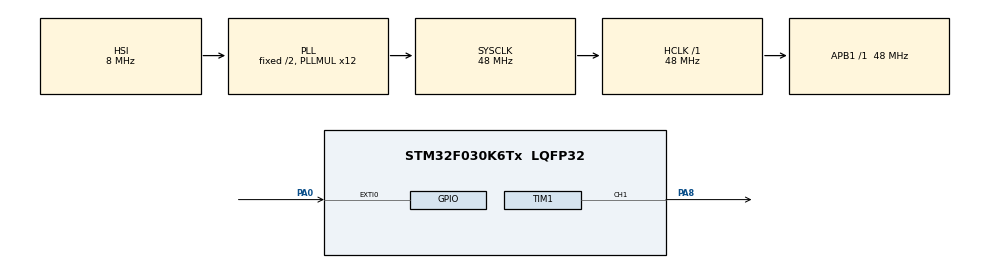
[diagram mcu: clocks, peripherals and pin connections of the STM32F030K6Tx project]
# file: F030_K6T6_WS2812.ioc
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Dma.Request0=TIM1_CH1
Dma.TIM1_CH1.0.Direction=DMA_MEMORY_TO_PERIPH
Dma.TIM1_CH1.0.Instance=DMA1_Channel2
Dma.TIM1_CH1.0.MemDataAlignment=DMA_MDATAALIGN_HALFWORD
Dma.TIM1_CH1.0.MemInc=DMA_MINC_DISABLE
Dma.TIM1_CH1.0.Mode=DMA_NORMAL
Dma.TIM1_CH1.0.PeriphDataAlignment=DMA_PDATAALIGN_HALFWORD
Dma.TIM1_CH1.0.PeriphInc=DMA_PINC_ENABLE
Dma.TIM1_CH1.0.Priority=DMA_PRIORITY_HIGH
Mcu.Family=STM32F0
Mcu.Name=STM32F030K6Tx
Mcu.Package=LQFP32
NVIC.DMA1_Channel2_3_IRQn=true\:1\:0\:true\:false\:true\:false\:true
NVIC.EXTI0_1_IRQn=true\:0\:0\:false\:false\:true\:true\:true
PA0.GPIO_ModeDefaultEXTI=GPIO_MODE_IT_FALLING
PA0.GPIO_PuPd=GPIO_PULLUP
PA0.Signal=GPXTI0
PA13.Mode=Serial_Wire
PA13.Signal=SYS_SWDIO
PA14.Mode=Serial_Wire
PA14.Signal=SYS_SWCLK
PA8.GPIO_Speed=GPIO_SPEED_FREQ_HIGH
PA8.Signal=S_TIM1_CH1
ProjectManager.HeapSize=0x200
ProjectManager.StackSize=0x400
ProjectManager.TargetToolchain=MDK-ARM V5.27
RCC.AHBFreq_Value=48000000
RCC.APB1Freq_Value=48000000
RCC.APB1TimFreq_Value=48000000
RCC.HCLKFreq_Value=48000000
RCC.PLLMUL=RCC_PLL_MUL12
RCC.SYSCLKFreq_VALUE=48000000
RCC.SYSCLKSource=RCC_SYSCLKSOURCE_PLLCLK
SH.S_TIM1_CH1.0=TIM1_CH1,PWM Generation1 CH1
TIM1.Channel-PWM\ Generation1\ CH1=TIM_CHANNEL_1
TIM1.Period=59
board=custom

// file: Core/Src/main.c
/* USER CODE BEGIN Header */
/**
  ******************************************************************************
  * @file           : main.c
  * @brief          : Main program body
  ******************************************************************************
  * @attention
  *
  * <h2><center>&copy; Copyright (c) 2022 STMicroelectronics.
  * All rights reserved.</center></h2>
  *
  * This software component is licensed by ST under BSD 3-Clause license,
  * the "License"; You may not use this file except in compliance with the
  * License. You may obtain a copy of the License at:
  *                        opensource.org/licenses/BSD-3-Clause
  *
  ******************************************************************************
  */
/* USER CODE END Header */
#include "main.h"

/* USER CODE BEGIN Includes */
#include "RGB_LED.h"
/* USER CODE END Includes */

/* USER CODE BEGIN PM */
#define NUM 60
uint16_t send_Buf[NUM] ={20};
/* USER CODE END PM */

TIM_HandleTypeDef htim1;
DMA_HandleTypeDef hdma_tim1_ch1;

void SystemClock_Config(void);
static void MX_GPIO_Init(void);
static void MX_DMA_Init(void);
static void MX_TIM1_Init(void);

/* USER CODE BEGIN 0 */
int i=0,biu=0;
/* USER CODE END 0 */

int main(void)
{

  /* MCU Configuration--------------------------------------------------------*/

  /* Reset of all peripherals, Initializes the Flash interface and the Systick. */
  HAL_Init();

  /* Configure the system clock */
  SystemClock_Config();

  /* Initialize all configured peripherals */
  MX_GPIO_Init();
  MX_DMA_Init();
  MX_TIM1_Init();
  /* USER CODE BEGIN 2 */
    for (i = 0; i < 8; i++)
    {
        send_Buf[i] =40 ;
    }
    for (i = 8; i < 24; i++)
    {
        send_Buf[i] =20 ;
    }

  /* USER CODE END 2 */

  /* Infinite loop */
  while (1)
  {

    /* USER CODE BEGIN 3 */
      HAL_TIM_PWM_Start_DMA(&htim1, TIM_CHANNEL_1,(uint32_t*)send_Buf,NUM);

      HAL_Delay(2000);
      HAL_TIM_PWM_Start_DMA(&htim1, TIM_CHANNEL_1,(uint32_t*)send_Buf,2);

      HAL_Delay(2000);

  }
  /* USER CODE END 3 */
}

void SystemClock_Config(void)
{
  RCC_OscInitTypeDef RCC_OscInitStruct = {0};
  RCC_ClkInitTypeDef RCC_ClkInitStruct = {0};

  /** Initializes the RCC Oscillators according to the specified parameters
  * in the RCC_OscInitTypeDef structure.
  */
  RCC_OscInitStruct.OscillatorType = RCC_OSCILLATORTYPE_HSI;
  RCC_OscInitStruct.HSIState = RCC_HSI_ON;
  RCC_OscInitStruct.HSICalibrationValue = RCC_HSICALIBRATION_DEFAULT;
  RCC_OscInitStruct.PLL.PLLState = RCC_PLL_ON;
  RCC_OscInitStruct.PLL.PLLSource = RCC_PLLSOURCE_HSI;
  RCC_OscInitStruct.PLL.PLLMUL = RCC_PLL_MUL12;
  RCC_OscInitStruct.PLL.PREDIV = RCC_PREDIV_DIV1;
  if (HAL_RCC_OscConfig(&RCC_OscInitStruct) != HAL_OK)
  {
    Error_Handler();
  }
  /** Initializes the CPU, AHB and APB buses clocks
  */
  RCC_ClkInitStruct.ClockType = RCC_CLOCKTYPE_HCLK|RCC_CLOCKTYPE_SYSCLK
                              |RCC_CLOCKTYPE_PCLK1;
  RCC_ClkInitStruct.SYSCLKSource = RCC_SYSCLKSOURCE_PLLCLK;
  RCC_ClkInitStruct.AHBCLKDivider = RCC_SYSCLK_DIV1;
  RCC_ClkInitStruct.APB1CLKDivider = RCC_HCLK_DIV1;

  if (HAL_RCC_ClockConfig(&RCC_ClkInitStruct, FLASH_LATENCY_1) != HAL_OK)
  {
    Error_Handler();
  }
}

static void MX_TIM1_Init(void)
{

  TIM_MasterConfigTypeDef sMasterConfig = {0};
  TIM_OC_InitTypeDef sConfigOC = {0};
  TIM_BreakDeadTimeConfigTypeDef sBreakDeadTimeConfig = {0};

  htim1.Instance = TIM1;
  htim1.Init.Prescaler = 0;
  htim1.Init.CounterMode = TIM_COUNTERMODE_UP;
  htim1.Init.Period = 59;
  htim1.Init.ClockDivision = TIM_CLOCKDIVISION_DIV1;
  htim1.Init.RepetitionCounter = 0;
  htim1.Init.AutoReloadPreload = TIM_AUTORELOAD_PRELOAD_DISABLE;
  if (HAL_TIM_PWM_Init(&htim1) != HAL_OK)
  {
    Error_Handler();
  }
  sMasterConfig.MasterOutputTrigger = TIM_TRGO_RESET;
  sMasterConfig.MasterSlaveMode = TIM_MASTERSLAVEMODE_DISABLE;
  if (HAL_TIMEx_MasterConfigSynchronization(&htim1, &sMasterConfig) != HAL_OK)
  {
    Error_Handler();
  }
  sConfigOC.OCMode = TIM_OCMODE_PWM1;
  sConfigOC.Pulse = 0;
  sConfigOC.OCPolarity = TIM_OCPOLARITY_HIGH;
  sConfigOC.OCNPolarity = TIM_OCNPOLARITY_HIGH;
  sConfigOC.OCFastMode = TIM_OCFAST_DISABLE;
  sConfigOC.OCIdleState = TIM_OCIDLESTATE_RESET;
  sConfigOC.OCNIdleState = TIM_OCNIDLESTATE_RESET;
  if (HAL_TIM_PWM_ConfigChannel(&htim1, &sConfigOC, TIM_CHANNEL_1) != HAL_OK)
  {
    Error_Handler();
  }
  sBreakDeadTimeConfig.OffStateRunMode = TIM_OSSR_DISABLE;
  sBreakDeadTimeConfig.OffStateIDLEMode = TIM_OSSI_DISABLE;
  sBreakDeadTimeConfig.LockLevel = TIM_LOCKLEVEL_OFF;
  sBreakDeadTimeConfig.DeadTime = 0;
  sBreakDeadTimeConfig.BreakState = TIM_BREAK_DISABLE;
  sBreakDeadTimeConfig.BreakPolarity = TIM_BREAKPOLARITY_HIGH;
  sBreakDeadTimeConfig.AutomaticOutput = TIM_AUTOMATICOUTPUT_DISABLE;
  if (HAL_TIMEx_ConfigBreakDeadTime(&htim1, &sBreakDeadTimeConfig) != HAL_OK)
  {
    Error_Handler();
  }
  HAL_TIM_MspPostInit(&htim1);

}

static void MX_DMA_Init(void)
{

  /* DMA controller clock enable */
  __HAL_RCC_DMA1_CLK_ENABLE();

  /* DMA interrupt init */
  /* DMA1_Channel2_3_IRQn interrupt configuration */
  HAL_NVIC_SetPriority(DMA1_Channel2_3_IRQn, 1, 0);
  HAL_NVIC_EnableIRQ(DMA1_Channel2_3_IRQn);

}

static void MX_GPIO_Init(void)
{
  GPIO_InitTypeDef GPIO_InitStruct = {0};

  /* GPIO Ports Clock Enable */
  __HAL_RCC_GPIOA_CLK_ENABLE();

  /*Configure GPIO pin : PA0 */
  GPIO_InitStruct.Pin = GPIO_PIN_0;
  GPIO_InitStruct.Mode = GPIO_MODE_IT_FALLING;
  GPIO_InitStruct.Pull = GPIO_PULLUP;
  HAL_GPIO_Init(GPIOA, &GPIO_InitStruct);

  /* EXTI interrupt init*/
  HAL_NVIC_SetPriority(EXTI0_1_IRQn, 0, 0);
  HAL_NVIC_EnableIRQ(EXTI0_1_IRQn);

}

/* USER CODE BEGIN 4 */
void HAL_TIM_PWM_PulseFinishedCallback(TIM_HandleTypeDef *htim)
{

        HAL_TIM_PWM_Stop_DMA(&htim1, TIM_CHANNEL_1);

}
void HAL_GPIO_EXTI_Callback(uint16_t GPIO_Pin)
{
    HAL_TIM_PWM_Start_DMA(&htim1, TIM_CHANNEL_1,(uint32_t*)send_Buf,NUM);
}
/* USER CODE END 4 */

void Error_Handler(void)
{
  __disable_irq();
  while (1)
  {
  }
}

/************************ (C) COPYRIGHT STMicroelectronics *****END OF FILE****/
